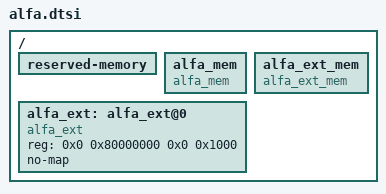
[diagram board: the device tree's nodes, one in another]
/include/ "system-conf.dtsi"
/ {
    reserved-memory {
        #address-cells = <2>;
        #size-cells = <2>;
        ranges;

    };

    alfa_mem: alfa_mem {
        status = "okay";
        compatible = "alfa_mem";
    };

    alfa_ext: alfa_ext@0 {
        compatible = "alfa_ext";
        reg = <0x0 0x80000000 0x0 0x1000>; // 4KB region for FPGA device
        status = "okay";
        no-map;
    };

    alfa_ext_mem: alfa_ext_mem {
        status = "okay";
        compatible = "alfa_ext_mem";
    };
};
